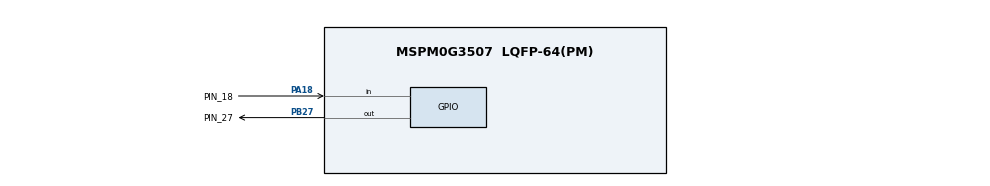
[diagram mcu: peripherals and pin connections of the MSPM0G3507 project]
/**
 * AI AGENTS: Do not edit this file directly. There is no validation or error feedback when
 * editing manually — mistakes will be silent until the file is loaded in SysConfig.
 * Use the SysConfig MCP server instead to make changes with immediate error reporting.
 *
 * These arguments were used when this file was generated. They will be automatically applied on subsequent loads
 * via the GUI or CLI. Run CLI with '--help' for additional information on how to override these arguments.
 * @cliArgs --device "MSPM0G350X" --part "Default" --package "LQFP-64(PM)" --product "mspm0_sdk@2.11.00.07"
 * @v2CliArgs --device "MSPM0G3507" --package "LQFP-64(PM)" --product "mspm0_sdk@2.11.00.07"
 * @versions {"tool":"1.28.1+4785"}
 */

/**
 * Import the modules used in this configuration.
 */
const GPIO    = scripting.addModule("/ti/driverlib/GPIO", {}, false);
const GPIO1   = GPIO.addInstance();
const GPIO2   = GPIO.addInstance();
const SYSCTL  = scripting.addModule("/ti/driverlib/SYSCTL");
const SYSTICK = scripting.addModule("/ti/driverlib/SYSTICK");

/**
 * Write custom configuration values to the imported modules.
 */
GPIO1.$name                          = "LED";
GPIO1.port                           = "PORTB";
GPIO1.associatedPins[0].$name        = "PIN_27";
GPIO1.associatedPins[0].initialValue = "SET";
GPIO1.associatedPins[0].assignedPin  = "27";
GPIO1.associatedPins[0].pin.$assign  = "PB27";

const Board = scripting.addModule("/ti/driverlib/Board", {}, false);

GPIO2.$name                         = "KEY1";
GPIO2.port                          = "PORTA";
GPIO2.associatedPins.create(2);
GPIO2.associatedPins[0].$name       = "PIN_28";
GPIO2.associatedPins[0].direction   = "INPUT";
GPIO2.associatedPins[0].assignedPin = "28";
GPIO2.associatedPins[1].$name       = "PIN_18";
GPIO2.associatedPins[1].direction   = "INPUT";
GPIO2.associatedPins[1].assignedPin = "18";
GPIO2.associatedPins[1].interruptEn = true;
GPIO2.associatedPins[1].polarity    = "RISE";
GPIO2.associatedPins[1].pin.$assign = "PA18";

SYSCTL.forceDefaultClkConfig = true;

SYSTICK.periodEnable      = true;
SYSTICK.period            = 32000;
SYSTICK.interruptEnable   = true;
SYSTICK.systickEnable     = true;
SYSTICK.interruptPriority = "0";

/**
 * Pinmux solution for unlocked pins/peripherals. This ensures that minor changes to the automatic solver in a future
 * version of the tool will not impact the pinmux you originally saw.  These lines can be completely deleted in order to
 * re-solve from scratch.
 */
Board.peripheral.$suggestSolution            = "DEBUGSS";
Board.peripheral.swclkPin.$suggestSolution   = "PA20";
Board.peripheral.swdioPin.$suggestSolution   = "PA19";
GPIO2.associatedPins[0].pin.$suggestSolution = "PA28";
SYSCTL.peripheral.$suggestSolution           = "SYSCTL";
